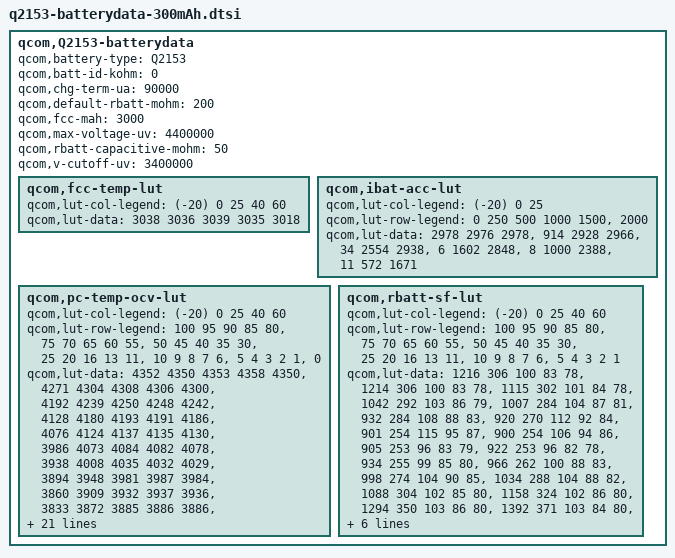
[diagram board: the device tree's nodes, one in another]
qcom,Q2153-batterydata {
	qcom,battery-type = "Q2153";
	qcom,batt-id-kohm = <0>;
	qcom,chg-term-ua = <90000>;
	qcom,default-rbatt-mohm = <200>;
	qcom,fcc-mah = <3000>;
	qcom,max-voltage-uv = <4400000>;
	qcom,rbatt-capacitive-mohm = <50>;
	qcom,v-cutoff-uv = <3400000>;

	qcom,fcc-temp-lut {
		qcom,lut-col-legend = <(-20) 0 25 40 60>;
		qcom,lut-data = <3038 3036 3039 3035 3018>;
	};

	qcom,ibat-acc-lut {
		qcom,lut-col-legend = <(-20) 0 25>;
		qcom,lut-row-legend = <0 250 500 1000 1500>,
					<2000>;
		qcom,lut-data = <2978 2976 2978>,
				<914 2928 2966>,
				<34 2554 2938>,
				<6 1602 2848>,
				<8 1000 2388>,
				<11 572 1671>;
	};

	qcom,pc-temp-ocv-lut {
		qcom,lut-col-legend = <(-20) 0 25 40 60>;
		qcom,lut-row-legend = <100 95 90 85 80>,
					<75 70 65 60 55>,
					<50 45 40 35 30>,
					<25 20 16 13 11>,
					<10 9 8 7 6>,
					<5 4 3 2 1>,
					<0>;
		qcom,lut-data = <4352 4350 4353 4358 4350>,
				<4271 4304 4308 4306 4300>,
				<4192 4239 4250 4248 4242>,
				<4128 4180 4193 4191 4186>,
				<4076 4124 4137 4135 4130>,
				<3986 4073 4084 4082 4078>,
				<3938 4008 4035 4032 4029>,
				<3894 3948 3981 3987 3984>,
				<3860 3909 3932 3937 3936>,
				<3833 3872 3885 3886 3886>,
				<3812 3841 3854 3854 3854>,
				<3794 3814 3828 3829 3828>,
				<3778 3794 3806 3808 3807>,
				<3762 3779 3788 3790 3788>,
				<3745 3766 3770 3769 3764>,
				<3729 3752 3753 3746 3735>,
				<3710 3733 3734 3726 3714>,
				<3690 3717 3714 3706 3693>,
				<3672 3705 3696 3688 3676>,
				<3658 3696 3689 3682 3670>,
				<3650 3692 3687 3681 3669>,
				<3640 3687 3686 3679 3667>,
				<3628 3681 3683 3676 3664>,
				<3614 3673 3678 3672 3658>,
				<3595 3658 3664 3659 3640>,
				<3572 3634 3633 3626 3605>,
				<3542 3596 3586 3580 3556>,
				<3499 3536 3522 3514 3494>,
				<3434 3454 3434 3428 3408>,
				<3322 3318 3294 3293 3275>,
				<3078 3064 3032 3000 3000>;
	};

	qcom,rbatt-sf-lut {
		qcom,lut-col-legend = <(-20) 0 25 40 60>;
		qcom,lut-row-legend = <100 95 90 85 80>,
					<75 70 65 60 55>,
					<50 45 40 35 30>,
					<25 20 16 13 11>,
					<10 9 8 7 6>,
					<5 4 3 2 1>;
		qcom,lut-data = <1216 306 100 83 78>,
				<1214 306 100 83 78>,
				<1115 302 101 84 78>,
				<1042 292 103 86 79>,
				<1007 284 104 87 81>,
				<932 284 108 88 83>,
				<920 270 112 92 84>,
				<901 254 115 95 87>,
				<900 254 106 94 86>,
				<905 253 96 83 79>,
				<922 253 96 82 78>,
				<934 255 99 85 80>,
				<966 262 100 88 83>,
				<998 274 104 90 85>,
				<1034 288 104 88 82>,
				<1088 304 102 85 80>,
				<1158 324 102 86 80>,
				<1294 350 103 86 80>,
				<1392 371 103 84 80>,
				<1368 378 104 86 80>,
				<1378 380 106 87 82>,
				<1486 392 108 88 83>,
				<1596 406 111 90 85>,
				<1740 419 114 93 86>,
				<1914 436 115 92 84>,
				<2140 449 112 88 82>,
				<2438 470 112 89 83>,
				<2878 502 116 90 84>,
				<3612 555 124 95 88>,
				<5872 1110 247 190 112>;
	};
};
